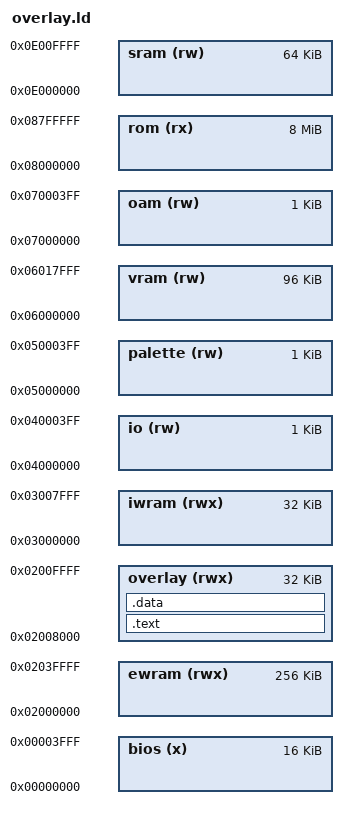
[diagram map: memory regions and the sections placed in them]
MEMORY {
	bios	(x)	: ORIGIN = 0x00000000, LENGTH = 16K
	ewram	(rwx)	: ORIGIN = 0x02000000, LENGTH = 256K
	overlay (rwx)	: ORIGIN = 0x02008000, LENGTH = 32K
	iwram	(rwx)	: ORIGIN = 0x03000000, LENGTH = 32K
	io	(rw)	: ORIGIN = 0x04000000, LENGTH = 1K
	palette	(rw)	: ORIGIN = 0x05000000, LENGTH = 1K
	vram	(rw)	: ORIGIN = 0x06000000, LENGTH = 96K
	oam	(rw)	: ORIGIN = 0x07000000, LENGTH = 1K
	rom	(rx)	: ORIGIN = 0x08000000, LENGTH = 8M
	sram	(rw)	: ORIGIN = 0x0E000000, LENGTH = 64K
}

SECTIONS {
	.text : {
		src/overlays/rom_7e7574/exports.o(.text)
		asm/overlays/rom_7e7574/ovl_30_b.o(.text)
		src/overlays/rom_7e7574/ovl_30_c_a_a.o(.text)
		src/overlays/rom_7e7574/ovl_30_c_a_b.o(.text)
		src/overlays/rom_7e7574/ovl_30_c_a_c.o(.text)
		asm/overlays/rom_7e7574/ovl_30_c_b.o(.text)
		src/overlays/rom_7e7574/ovl_30_c_c_834c.o(.text)
		src/overlays/rom_7e7574/ovl_30_c_c_8474.o(.text)
		src/overlays/rom_7e7574/ovl_30_c_c_8608.o(.text)
		asm/overlays/rom_7e7574/ovl_30_c_c.o(.text.after_8608)
		src/overlays/rom_7e7574/ovl_30_c_c_88c0.o(.text)
		asm/overlays/rom_7e7574/ovl_9dc_a_a.o(.text)
		asm/overlays/rom_7e7574/ovl_9dc_a_b.o(.text)
		src/overlays/rom_7e7574/ovl_9dc_a_c_a.o(.text)
		asm/overlays/rom_7e7574/ovl_9dc_a_c_a_b.o(.text)
		asm/overlays/rom_7e7574/ovl_9dc_a_c_a_c.o(.text)
		asm/overlays/rom_7e7574/ovl_9dc_a_c_b.o(.text)
		src/overlays/rom_7e7574/ovl_9dc_a_c_c_a_a_b.o(.text)
		src/overlays/rom_7e7574/ovl_9dc_a_c_c_a_a_c_a.o(.text)
		src/overlays/rom_7e7574/ovl_9dc_a_c_c_a_a_c_b.o(.text)
		src/overlays/rom_7e7574/ovl_9dc_a_c_c_a_a_c_c_8c90.o(.text)
		asm/overlays/rom_7e7574/ovl_9dc_a_c_c_a_a_c_c.o(.text.after_8c90)
		src/overlays/rom_7e7574/ovl_9dc_a_c_c_a_a_c_c_8ce0.o(.text)
		asm/overlays/rom_7e7574/ovl_9dc_a_c_c_a_a_c_c.o(.text.after_8ce0)
		src/overlays/rom_7e7574/ovl_9dc_a_c_c_a_a_c_c_8dcc.o(.text)
		src/overlays/rom_7e7574/ovl_9dc_a_c_c_a_a_c_c_8e30.o(.text)
		src/overlays/rom_7e7574/ovl_9dc_a_c_c_a_a_c_c_8e80.o(.text)
		src/overlays/rom_7e7574/ovl_9dc_a_c_c_a_a_c_c_8ee0.o(.text)
		src/overlays/rom_7e7574/ovl_9dc_a_c_c_a_a_c_c_8f30.o(.text)
		asm/overlays/rom_7e7574/ovl_9dc_a_c_c_a_a_c_c.o(.text.after_8ee0)
		asm/overlays/rom_7e7574/ovl_9dc_a_c_c_a_b.o(.text)
		asm/overlays/rom_7e7574/ovl_9dc_a_c_c_b.o(.text)
		asm/overlays/rom_7e7574/ovl_9dc_a_c_c_c_a_b.o(.text)
		asm/overlays/rom_7e7574/ovl_9dc_a_c_c_c_a_c_b.o(.text)
		asm/overlays/rom_7e7574/ovl_9dc_a_c_c_c_b.o(.text)
		asm/overlays/rom_7e7574/ovl_9dc_a_c_c_c_c_b.o(.text)
		asm/overlays/rom_7e7574/ovl_9dc_a_c_c_c_c_c.o(.text)
		asm/overlays/rom_7e7574/ovl_9dc_b.o(.text)
		src/overlays/rom_7e7574/ovl_9dc_c_a_a_a_a_90a8.o(.text)
		src/overlays/rom_7e7574/ovl_9dc_c_a_a_a_a_9108.o(.text)
		asm/overlays/rom_7e7574/ovl_9dc_c_a_a_a_a.o(.text.after_9108)
		src/overlays/rom_7e7574/ovl_9dc_c_a_a_a_a_92e0.o(.text)
		asm/overlays/rom_7e7574/ovl_9dc_c_a_a_a_b.o(.text)
		asm/overlays/rom_7e7574/ovl_9dc_c_a_a_a_c.o(.text)
		asm/overlays/rom_7e7574/ovl_9dc_c_a_a_b.o(.text)
		src/overlays/rom_7e7574/ovl_9dc_c_a_a_c_a_94cc.o(.text)
		asm/overlays/rom_7e7574/ovl_9dc_c_a_a_c_a.o(.text.after_94cc)
		asm/overlays/rom_7e7574/ovl_9dc_c_a_a_c_b.o(.text)
		asm/overlays/rom_7e7574/ovl_9dc_c_a_b.o(.text)
		asm/overlays/rom_7e7574/ovl_9dc_c_a_c_a_a.o(.text)
		asm/overlays/rom_7e7574/ovl_9dc_c_a_c_a_b.o(.text)
		src/overlays/rom_7e7574/ovl_9dc_c_a_c_a_c_9718.o(.text)
		src/overlays/rom_7e7574/ovl_9dc_c_a_c_a_c_975c.o(.text)
		src/overlays/rom_7e7574/ovl_9dc_c_a_c_a_c_97bc.o(.text)
		asm/overlays/rom_7e7574/ovl_9dc_c_a_c_a_c.o(.text.after_97bc)
		asm/overlays/rom_7e7574/ovl_9dc_c_a_c_b.o(.text)
		asm/overlays/rom_7e7574/ovl_9dc_c_a_c_c_a_a_a.o(.text)
		src/overlays/rom_7e7574/ovl_9dc_c_a_c_c_a_a_a_99e8.o(.text)
		asm/overlays/rom_7e7574/ovl_9dc_c_a_c_c_a_a_a.o(.text.after_99e8)
		src/overlays/rom_7e7574/ovl_9dc_c_a_c_c_a_a_a_9ab0.o(.text)
		asm/overlays/rom_7e7574/ovl_9dc_c_a_c_c_a_a_a.o(.text.after_9ab0)
		src/overlays/rom_7e7574/ovl_9dc_c_a_c_c_a_a_a_9c4c.o(.text)
		src/overlays/rom_7e7574/ovl_9dc_c_a_c_c_a_a_a_9ca4.o(.text)
		src/overlays/rom_7e7574/ovl_9dc_c_a_c_c_a_a_a_9cf0.o(.text)
		src/overlays/rom_7e7574/ovl_9dc_c_a_c_c_a_a_a_9d60.o(.text)
		src/overlays/rom_7e7574/ovl_9dc_c_a_c_c_a_a_a_9dc4.o(.text)
		src/overlays/rom_7e7574/ovl_9dc_c_a_c_c_a_a_a_9e2c.o(.text)
		asm/overlays/rom_7e7574/ovl_9dc_c_a_c_c_a_a_a.o(.text.after_9e2c)
		src/overlays/rom_7e7574/ovl_9dc_c_a_c_c_a_a_a_a06c.o(.text)
		src/overlays/rom_7e7574/ovl_9dc_c_a_c_c_a_a_a_a0cc.o(.text)
		asm/overlays/rom_7e7574/ovl_9dc_c_a_c_c_a_a_a.o(.text.after_a0cc)
		src/overlays/rom_7e7574/ovl_9dc_c_a_c_c_a_a_b.o(.text)
		src/overlays/rom_7e7574/ovl_9dc_c_a_c_c_a_a_c_a2d4.o(.text)
		src/overlays/rom_7e7574/ovl_9dc_c_a_c_c_a_a_c_a308.o(.text)
		src/overlays/rom_7e7574/ovl_9dc_c_a_c_c_a_a_c_a38c.o(.text)
		src/overlays/rom_7e7574/ovl_9dc_c_a_c_c_a_a_c_a410.o(.text)
		src/overlays/rom_7e7574/ovl_9dc_c_a_c_c_a_a_c_a468.o(.text)
		asm/overlays/rom_7e7574/ovl_9dc_c_a_c_c_a_b.o(.text)
		asm/overlays/rom_7e7574/ovl_9dc_c_a_c_c_b.o(.text)
		asm/overlays/rom_7e7574/ovl_9dc_c_a_c_c_c_b.o(.text)
		asm/overlays/rom_7e7574/ovl_9dc_c_b.o(.text)
		asm/overlays/rom_7e7574/ovl_9dc_c_c_a_a.o(.text)
		src/overlays/rom_7e7574/ovl_9dc_c_c_a_a_a69c.o(.text)
		asm/overlays/rom_7e7574/ovl_9dc_c_c_a_a.o(.text.after_a69c)
		asm/overlays/rom_7e7574/ovl_9dc_c_c_a_b.o(.text)
		asm/overlays/rom_7e7574/ovl_9dc_c_c_a_c_a_a.o(.text)
		asm/overlays/rom_7e7574/ovl_9dc_c_c_a_c_a_b.o(.text)
		asm/overlays/rom_7e7574/ovl_9dc_c_c_a_c_a_c_a_b.o(.text)
		asm/overlays/rom_7e7574/ovl_9dc_c_c_a_c_a_c_a_c_a_b.o(.text)
		asm/overlays/rom_7e7574/ovl_9dc_c_c_a_c_a_c_a_c_b.o(.text)
		asm/overlays/rom_7e7574/ovl_9dc_c_c_a_c_a_c_b.o(.text)
		asm/overlays/rom_7e7574/ovl_9dc_c_c_a_c_a_c_c.o(.text)
		asm/overlays/rom_7e7574/ovl_9dc_c_c_a_c_b.o(.text)
		asm/overlays/rom_7e7574/ovl_9dc_c_c_b.o(.text)
		asm/overlays/rom_7e7574/ovl_9dc_c_c_c_a_a_a.o(.text)
		asm/overlays/rom_7e7574/ovl_9dc_c_c_c_a_a_b.o(.text)
		asm/overlays/rom_7e7574/ovl_9dc_c_c_c_a_a_c.o(.text)
		asm/overlays/rom_7e7574/ovl_9dc_c_c_c_a_b.o(.text)
		asm/overlays/rom_7e7574/ovl_9dc_c_c_c_b.o(.text)
		asm/overlays/rom_7e7574/ovl_9dc_c_c_c_c_b.o(.text)
		asm/overlays/rom_7e7574/ovl_9dc_c_c_c_c_c_b.o(.text)
		asm/overlays/rom_7e7574/ovl_9dc_c_c_c_c_c_c.o(.text)
		src/overlays/rom_7e7574/imports.o(.text)
		src/lib/call_via.o(.text)
		asm/overlays/common/common2_a.o(.text)
		src/overlays/common/common2_a_254.o(.text)
		src/overlays/common/common2_a_28c.o(.text)
		asm/overlays/common/common2_b.o(.text)
		asm/overlays/common/common2_c_b.o(.text)
		asm/overlays/common/common2_c_c_b.o(.text)
		asm/overlays/common/common2_c_c_c_b.o(.text)
		asm/overlays/common/common2_c_c_c_c_a.o(.text)
		asm/overlays/common/common2_c_c_c_c_b.o(.text)
		asm/overlays/common/common2_c_c_c_c_c_b.o(.text)
		asm/overlays/common/common2_c_c_c_c_c_c_b.o(.text)
		src/overlays/common/common2_c_c_c_c_c_c_c_a_41c.o(.text)
		asm/overlays/common/common2_c_c_c_c_c_c_c_a.o(.text.after_41c)
		asm/overlays/common/common2_c_c_c_c_c_c_c_b.o(.text)
		asm/overlays/common/common2_c_c_c_c_c_c_c_c_b.o(.text)
		asm/overlays/common/common2_c_c_c_c_c_c_c_c_c_b.o(.text)
		asm/overlays/common/common2_c_c_c_c_c_c_c_c_c_c.o(.text)
	} > overlay

	.data : {
		asm/overlays/rom_7e7574/ovl_30_c_c.o(.data)
		asm/overlays/common/common2_c_c_c_c_c_c_c_c_c_c.o(.data)
		asm/overlays/rom_7e7574/ovl_9dc_c_c_c_c_c_c.o(.data)
	} > overlay

	/DISCARD/ : {
		*(*)
	}
}
